# Cortex_M33 register map
Vendor: ARM Ltd.; File version: 1.3
CPU: CM33 r0p0, little endian, MPU, no FPU, vendor SysTick, 8 interrupt priority bits
Registers are 32-bit, read-write, no defined reset value unless marked. A register's access mark holds for its fields unless they carry their own. Offsets are from the block's base; [hi:lo] are bit positions; {n}, {i} and the like mark numbered series; 'fields as' and 'values as' point back to an identical list.

## SCB — System Control Block
Base 0xE000ED00
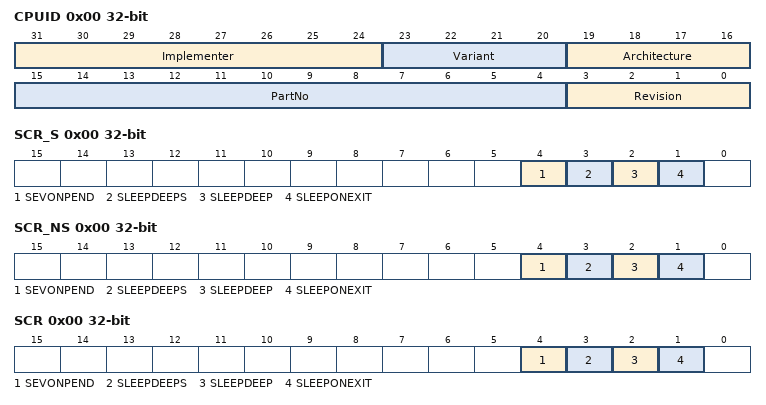
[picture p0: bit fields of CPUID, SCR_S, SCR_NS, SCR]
0x00 CPUID ro
  [31:24] Implementer, [23:20] Variant, [19:16] Architecture, [15:4] PartNo, [3:0] Revision
0x00 SCR_S
  [4] SEVONPEND, [3] SLEEPDEEPS, [2] SLEEPDEEP, [1] SLEEPONEXIT
0x00 SCR_NS
  [4] SEVONPEND, [3] SLEEPDEEPS, [2] SLEEPDEEP, [1] SLEEPONEXIT
0x00 SCR
  [4] SEVONPEND, [3] SLEEPDEEPS, [2] SLEEPDEEP, [1] SLEEPONEXIT
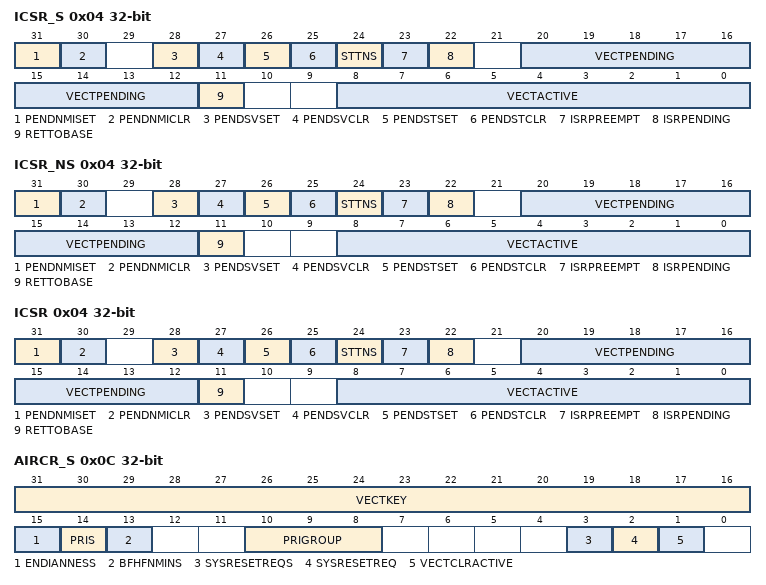
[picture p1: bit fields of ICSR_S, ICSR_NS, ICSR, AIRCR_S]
0x04 ICSR_S
  [31] PENDNMISET, [30] PENDNMICLR, [28] PENDSVSET, [27] PENDSVCLR, [26] PENDSTSET, [25] PENDSTCLR, [24] STTNS, [23] ISRPREEMPT, [22] ISRPENDING, [20:12] VECTPENDING, [11] RETTOBASE, [8:0] VECTACTIVE
0x04 ICSR_NS
  fields as ICSR_S
0x04 ICSR
  fields as ICSR_S
0x08 VTOR_S
  [31:7] TBLOFF
0x08 VTOR_NS
  [31:7] TBLOFF
0x08 VTOR
  [31:7] TBLOFF
0x0C AIRCR_S
  [31:16] VECTKEY, [15] ENDIANNESS, [14] PRIS, [13] BFHFNMINS, [10:8] PRIGROUP, [3] SYSRESETREQS, [2] SYSRESETREQ, [1] VECTCLRACTIVE
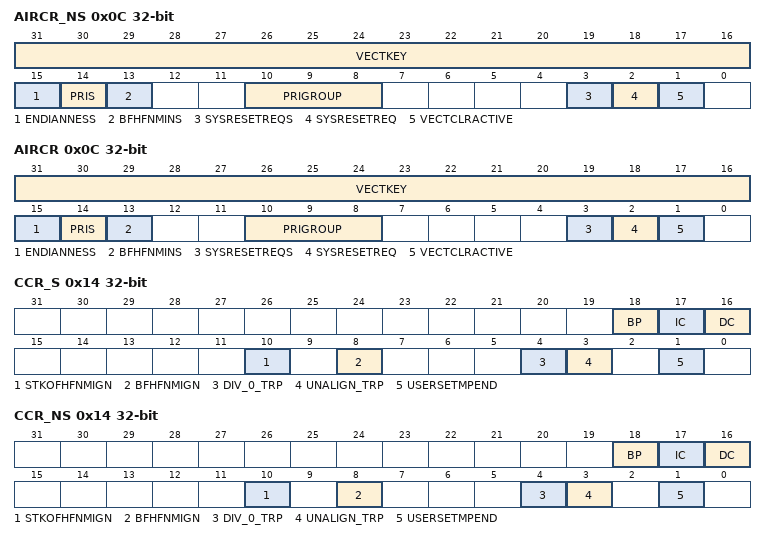
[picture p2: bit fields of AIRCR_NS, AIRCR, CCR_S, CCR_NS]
0x0C AIRCR_NS
  fields as AIRCR_S
0x0C AIRCR
  fields as AIRCR_S
0x14 CCR_S
  [18] BP, [17] IC, [16] DC, [10] STKOFHFNMIGN, [8] BFHFNMIGN, [4] DIV_0_TRP, [3] UNALIGN_TRP, [1] USERSETMPEND
0x14 CCR_NS
  fields as CCR_S
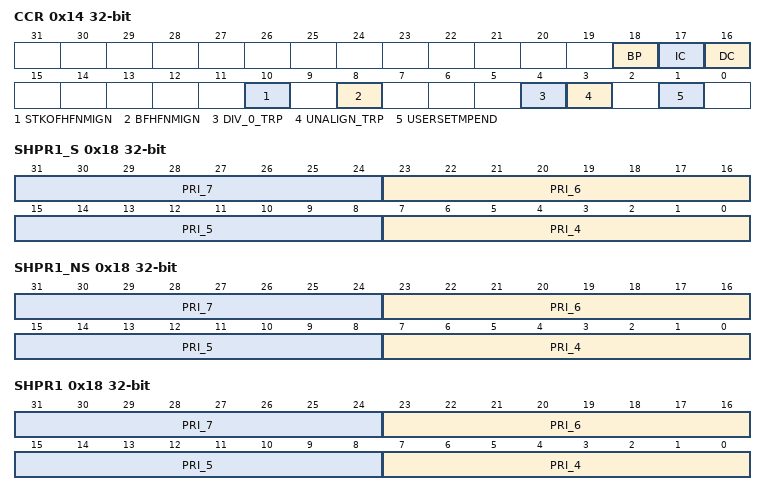
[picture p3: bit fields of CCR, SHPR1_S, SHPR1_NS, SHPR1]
0x14 CCR
  fields as CCR_S
0x18 SHPR1_S
  [8n-25:8n-32] PRI_{n} (n=4..7)
0x18 SHPR1_NS
  [8n-25:8n-32] PRI_{n} (n=4..7)
0x18 SHPR1
  [8n-25:8n-32] PRI_{n} (n=4..7)
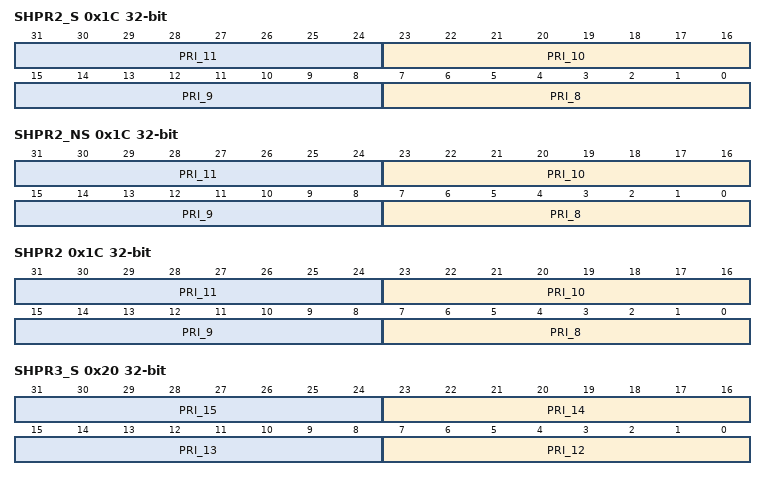
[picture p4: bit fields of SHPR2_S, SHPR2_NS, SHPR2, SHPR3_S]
0x1C SHPR2_S
  [8n-57:8n-64] PRI_{n} (n=8..11)
0x1C SHPR2_NS
  [8n-57:8n-64] PRI_{n} (n=8..11)
0x1C SHPR2
  [8n-57:8n-64] PRI_{n} (n=8..11)
0x20 SHPR3_S
  [8n-89:8n-96] PRI_{n} (n=12..15)
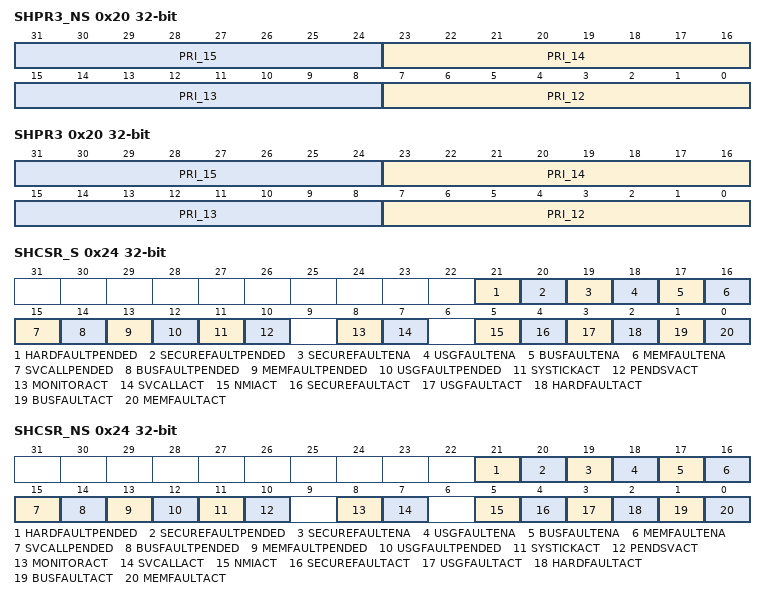
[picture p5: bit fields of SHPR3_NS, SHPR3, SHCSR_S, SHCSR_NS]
0x20 SHPR3_NS
  [8n-89:8n-96] PRI_{n} (n=12..15)
0x20 SHPR3
  [8n-89:8n-96] PRI_{n} (n=12..15)
0x24 SHCSR_S
  [21] HARDFAULTPENDED, [20] SECUREFAULTPENDED, [19] SECUREFAULTENA, [18] USGFAULTENA, [17] BUSFAULTENA, [16] MEMFAULTENA, [15] SVCALLPENDED, [14] BUSFAULTPENDED, [13] MEMFAULTPENDED, [12] USGFAULTPENDED, [11] SYSTICKACT, [10] PENDSVACT, [8] MONITORACT, [7] SVCALLACT, [5] NMIACT, [4] SECUREFAULTACT, [3] USGFAULTACT, [2] HARDFAULTACT, [1] BUSFAULTACT, [0] MEMFAULTACT
0x24 SHCSR_NS
  fields as SHCSR_S
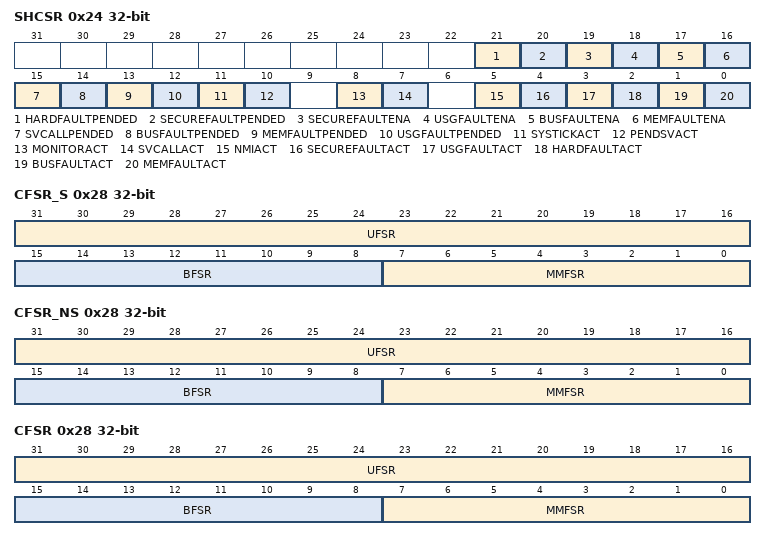
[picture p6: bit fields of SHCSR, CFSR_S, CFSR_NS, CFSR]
0x24 SHCSR
  fields as SHCSR_S
0x28 CFSR_S
  [31:16] UFSR, [15:8] BFSR, [7:0] MMFSR
0x28 CFSR_NS
  [31:16] UFSR, [15:8] BFSR, [7:0] MMFSR
0x28 CFSR
  [31:16] UFSR, [15:8] BFSR, [7:0] MMFSR
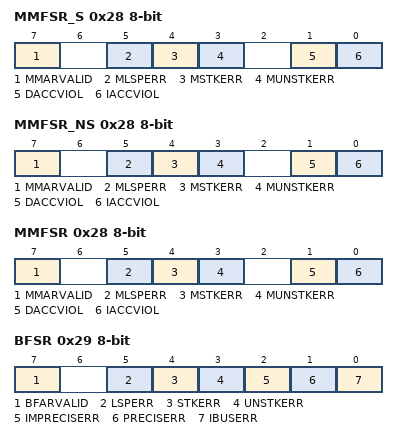
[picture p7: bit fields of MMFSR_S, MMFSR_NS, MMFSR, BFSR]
0x28 MMFSR_S 8-bit
  [7] MMARVALID, [5] MLSPERR, [4] MSTKERR, [3] MUNSTKERR, [1] DACCVIOL, [0] IACCVIOL
0x28 MMFSR_NS 8-bit
  fields as MMFSR_S
0x28 MMFSR 8-bit
  fields as MMFSR_S
0x29 BFSR 8-bit
  [7] BFARVALID, [5] LSPERR, [4] STKERR, [3] UNSTKERR, [2] IMPRECISERR, [1] PRECISERR, [0] IBUSERR
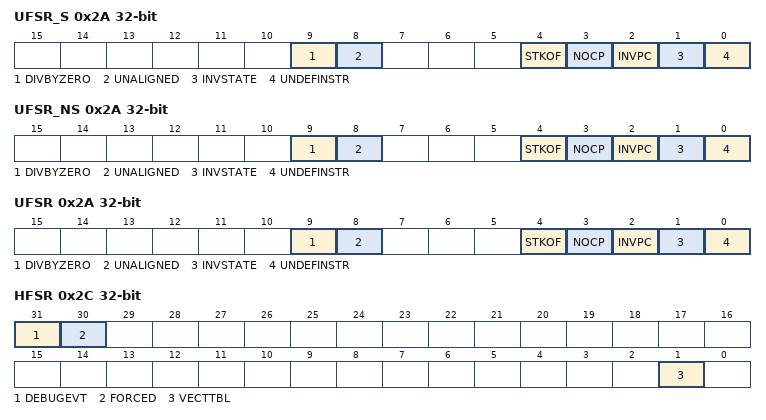
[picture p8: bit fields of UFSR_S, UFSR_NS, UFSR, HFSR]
0x2A UFSR_S size not given
  [9] DIVBYZERO, [8] UNALIGNED, [4] STKOF, [3] NOCP, [2] INVPC, [1] INVSTATE, [0] UNDEFINSTR
0x2A UFSR_NS size not given
  fields as UFSR_S
0x2A UFSR size not given
  fields as UFSR_S
0x2C HFSR
  [31] DEBUGEVT, [30] FORCED, [1] VECTTBL
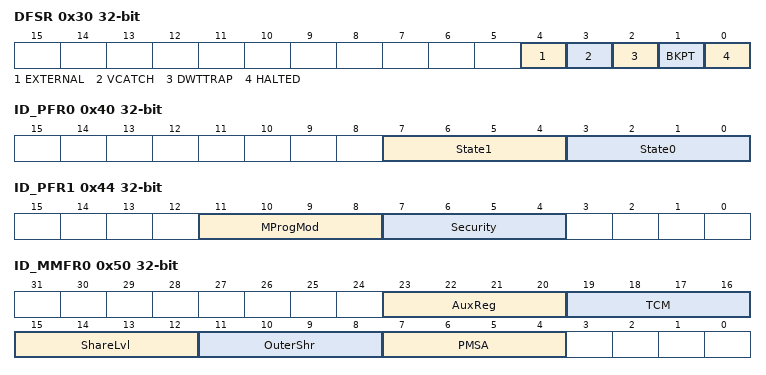
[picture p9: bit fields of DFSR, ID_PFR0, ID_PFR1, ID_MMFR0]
0x30 DFSR
  [4] EXTERNAL, [3] VCATCH, [2] DWTTRAP, [1] BKPT, [0] HALTED
0x34 MMFAR_S
  [31:0] ADDRESS
0x34 MMFAR_NS
  [31:0] ADDRESS
0x34 MMFAR
  [31:0] ADDRESS
0x38 BFAR
  [31:0] ADDRESS
0x3C AFSR
0x40 ID_PFR0 ro
  [7:4] State1 — State one
  [3:0] State0 — State two
0x44 ID_PFR1 ro
  [11:8] MProgMod, [7:4] Security
0x48 ID_DFR0 ro
  [23:20] MProfDbg
0x4C ID_AFR0 ro
0x50 ID_MMFR0 ro
  [23:20] AuxReg, [19:16] TCM, [15:12] ShareLvl, [11:8] OuterShr, [7:4] PMSA
0x54 ID_MMFR1 ro
0x58 ID_MMFR2 ro
  [27:24] WFIStall
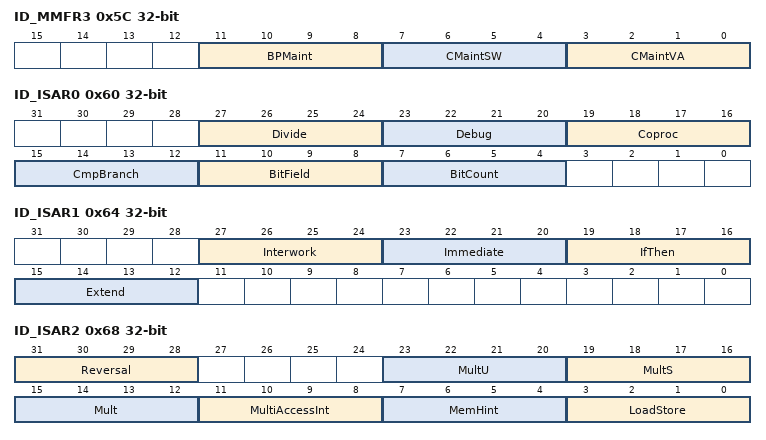
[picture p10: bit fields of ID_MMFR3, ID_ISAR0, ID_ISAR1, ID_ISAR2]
0x5C ID_MMFR3 ro
  [11:8] BPMaint, [7:4] CMaintSW, [3:0] CMaintVA
0x60 ID_ISAR0 ro
  [27:24] Divide, [23:20] Debug, [19:16] Coproc, [15:12] CmpBranch, [11:8] BitField, [7:4] BitCount
0x64 ID_ISAR1 ro
  [27:24] Interwork, [23:20] Immediate, [19:16] IfThen, [15:12] Extend
0x68 ID_ISAR2 ro
  [31:28] Reversal, [23:20] MultU, [19:16] MultS, [15:12] Mult, [11:8] MultiAccessInt, [7:4] MemHint, [3:0] LoadStore
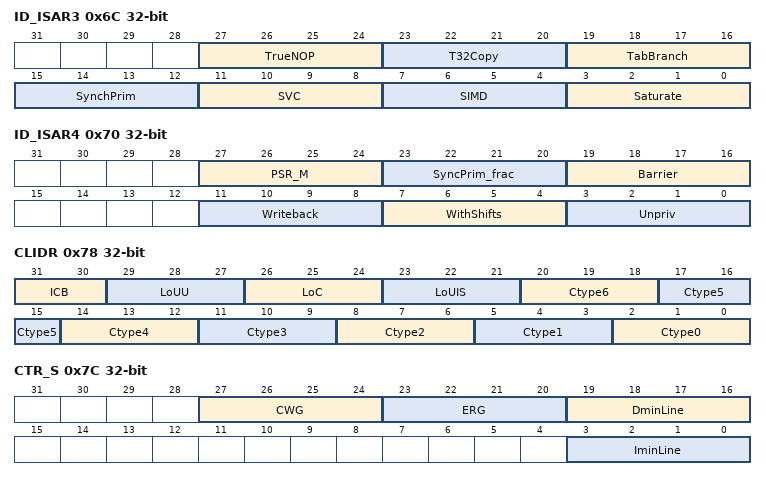
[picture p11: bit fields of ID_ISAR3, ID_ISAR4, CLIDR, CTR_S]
0x6C ID_ISAR3 ro
  [27:24] TrueNOP, [23:20] T32Copy, [19:16] TabBranch, [15:12] SynchPrim, [11:8] SVC, [7:4] SIMD, [3:0] Saturate
0x70 ID_ISAR4 ro
  [27:24] PSR_M, [23:20] SyncPrim_frac, [19:16] Barrier, [11:8] Writeback, [7:4] WithShifts, [3:0] Unpriv
0x74 ID_ISAR5 ro
0x78 CLIDR ro
  [31:30] ICB, [29:27] LoUU, [26:24] LoC, [23:21] LoUIS, [3n+2:3n] Ctype{n} (n=0..6)
0x7C CTR_S ro
  [27:24] CWG, [23:20] ERG, [19:16] DminLine, [3:0] IminLine
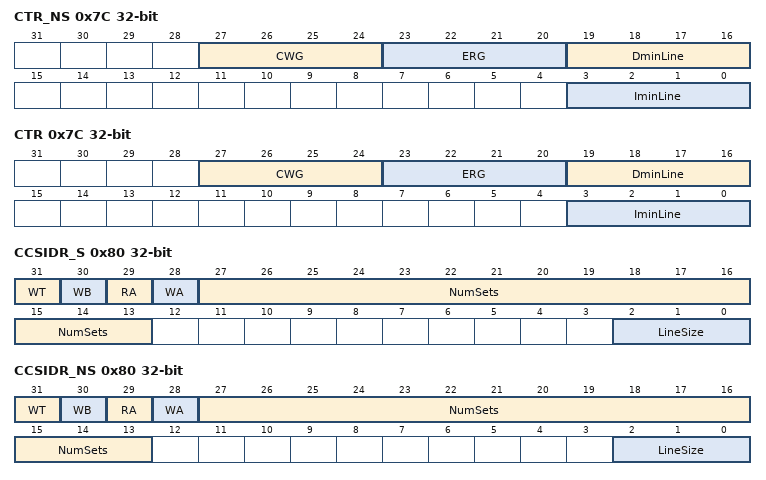
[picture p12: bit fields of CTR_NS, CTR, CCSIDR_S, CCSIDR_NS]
0x7C CTR_NS ro
  [27:24] CWG, [23:20] ERG, [19:16] DminLine, [3:0] IminLine
0x7C CTR ro
  [27:24] CWG, [23:20] ERG, [19:16] DminLine, [3:0] IminLine
0x80 CCSIDR_S ro
  [31] WT
  [30] WB — Writeback
  [29] RA
  [28] WA
  [27:13] NumSets
  [2:0] LineSize
0x80 CCSIDR_NS ro
  fields as CCSIDR_S
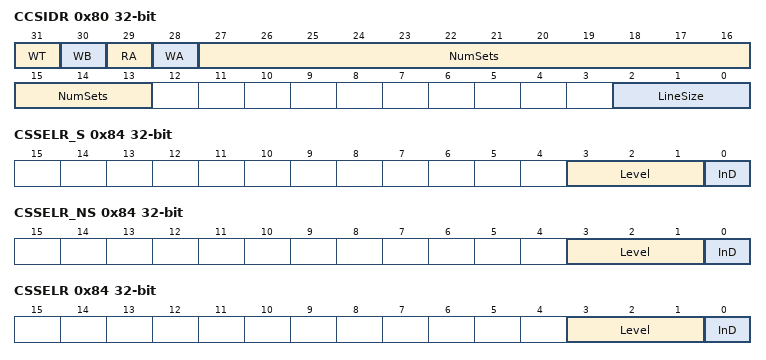
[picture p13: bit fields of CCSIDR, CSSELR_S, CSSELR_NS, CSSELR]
0x80 CCSIDR ro
  fields as CCSIDR_S
0x84 CSSELR_S
  [3:1] Level, [0] InD
0x84 CSSELR_NS
  [3:1] Level, [0] InD
0x84 CSSELR
  [3:1] Level, [0] InD
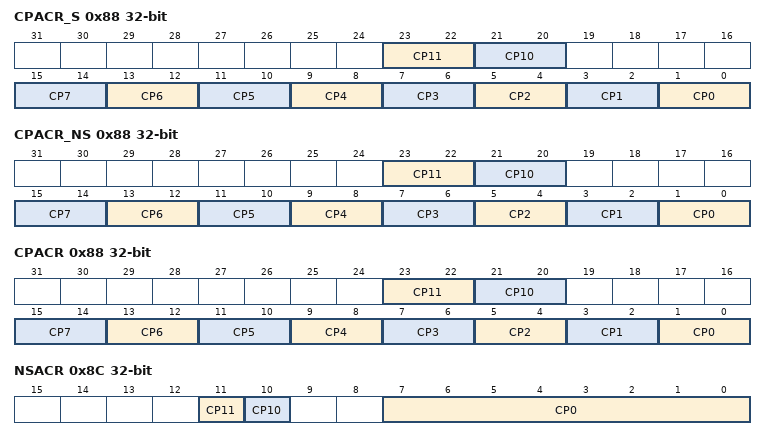
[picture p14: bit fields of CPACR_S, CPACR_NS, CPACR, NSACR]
0x88 CPACR_S
  [23:22] CP11, [21:20] CP10, [2n+1:2n] CP{n} (n=0..7)
0x88 CPACR_NS
  [23:22] CP11, [21:20] CP10, [2n+1:2n] CP{n} (n=0..7)
0x88 CPACR
  [23:22] CP11, [21:20] CP10, [2n+1:2n] CP{n} (n=0..7)
0x8C NSACR
  [11] CP11, [10] CP10, [7:0] CP0

## Notices in the file
Copyright (c) 2021 STMicroelectronics.
SPDX-License-Identifier: Apache-2.0
Licensed under the Apache License, Version 2.0 (the "License");
you may not use this file except in compliance with the License.
You may obtain a copy of the License at
http://www.apache.org/licenses/LICENSE-2.0
Unless required by applicable law or agreed to in writing, software
distributed under the License is distributed on an "AS IS" BASIS,
WITHOUT WARRANTIES OR CONDITIONS OF ANY KIND, either express or implied.
See the License for the specific language governing permissions and
limitations under the License.
